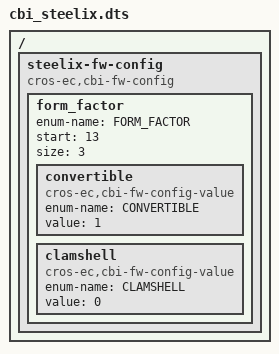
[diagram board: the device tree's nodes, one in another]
/* Copyright 2022 The Chromium OS Authors. All rights reserved.
 * Use of this source code is governed by a BSD-style license that can be
 * found in the LICENSE file.
 */

/ {
	steelix-fw-config {
		compatible = "cros-ec,cbi-fw-config";

		/*
		 * FW_CONFIG field to indicate the device is clamshell
		 * or convertible.
		 */
		form_factor {
			enum-name = "FORM_FACTOR";
			start = <13>;
			size = <3>;

			convertible {
				compatible = "cros-ec,cbi-fw-config-value";
				enum-name = "CONVERTIBLE";
				value = <1>;
			};
			clamshell {
				compatible = "cros-ec,cbi-fw-config-value";
				enum-name = "CLAMSHELL";
				value = <0>;
			};
		};
	};
};
